# PADCFG_CTRL0_CFG0 register map
Vendor: Texas Instruments
Registers are 32-bit, access per field, reset 0x8214007 unless marked. A register's access mark holds for its fields unless they carry their own. Offsets are as the file gives them; [hi:lo] are bit positions; {n}, {i} and the like mark numbered series; 'fields as' and 'values as' point back to an identical list.

## PADCFG_CTRL0_CFG0 (part 2 of 2)
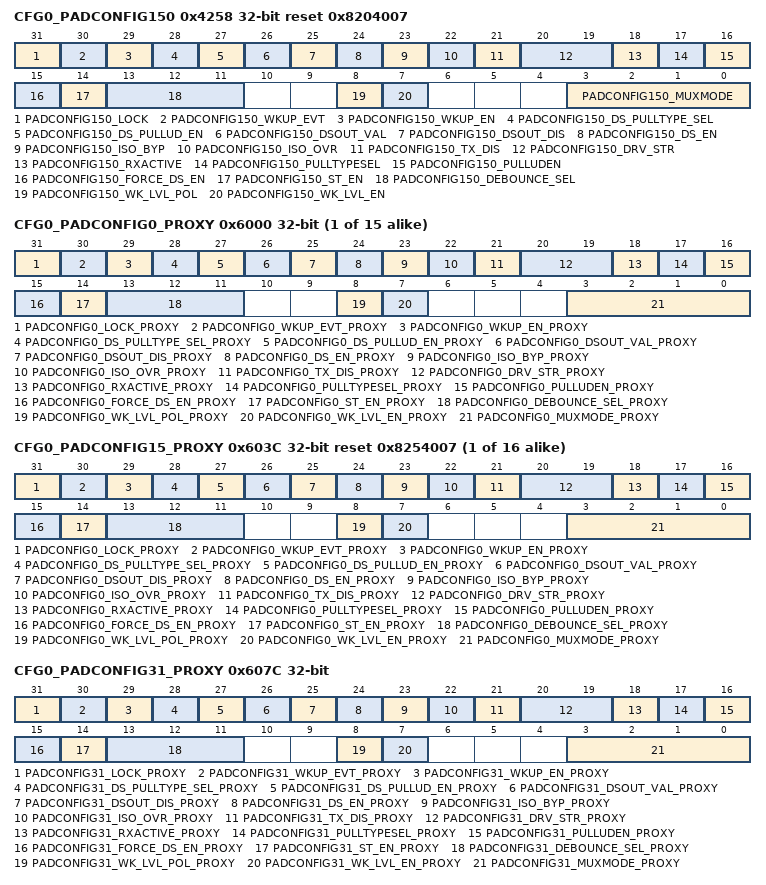
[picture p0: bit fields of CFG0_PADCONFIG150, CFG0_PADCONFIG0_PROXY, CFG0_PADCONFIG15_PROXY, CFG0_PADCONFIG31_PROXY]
0x4258 CFG0_PADCONFIG150 reset 0x8204007
  [31] PADCONFIG150_LOCK rw — Lock 0 - Padconfig register is unlocked 1 - Padconfig register is locked from further writes
  [30] PADCONFIG150_WKUP_EVT ro — Wakeup event status 0 - No wake event on pin 1 - Wake event occurred on pin
  [29] PADCONFIG150_WKUP_EN rw — Wakeup enable 0 - Wakeup operation disabled 1 - Wakeup operation enabled
  [28] PADCONFIG150_DS_PULLTYPE_SEL rw — Deep Sleep pull-up/down selection 0 - Offmode pulldown selected 1 - Offmode pullup selected
  [27] PADCONFIG150_DS_PULLUD_EN rw — Deep Sleep pull-up/down enable (active low) 0 - Pullup / pulldown is enabled 1 - Pullup / pulldown is disabled
  [26] PADCONFIG150_DSOUT_VAL rw — Deep Sleep output value 0 - Output value is 0 1 - Output value is 1
  [25] PADCONFIG150_DSOUT_DIS rw — Deep Sleep output disable 0 - Output enabled 1 - Output disabled
  [24] PADCONFIG150_DS_EN rw — Deep Sleep override control 0 - IO keeps its previous state when Deep Sleep mode is active 1 - IO state is forced to OFF mode value when Deep Sleep mode is active
  [23] PADCONFIG150_ISO_BYP rw — Isolation Bypass 0 - IO isolation is preserved 1 - IO isolation is bypassed
  [22] PADCONFIG150_ISO_OVR rw — Isolation Override 0 - IO isolation is preserved 1 - IO isolation is overridden
  [21] PADCONFIG150_TX_DIS rw — Driver Disable 0 - Driver is enabled 1 - Driver is disabled
  [20:19] PADCONFIG150_DRV_STR rw — Drive Strength Control . Selects the drive strength value for LVCMOS pins. (Does not apply to other pin types)
  [18] PADCONFIG150_RXACTIVE rw — Input enable for the Pad 0 - Receiver disabled 1 - Receiver enabled
  [17] PADCONFIG150_PULLTYPESEL rw — Pad Pullup / Pulldown type selection 0 - Pulldown selected 1 - Pullup selected
  [16] PADCONFIG150_PULLUDEN rw — Pad Pullup / Pulldown enable. This is an active low signal. 0 - Pullup / Pulldown enabled 1 - Pullup / Pulldown disabled
  [15] PADCONFIG150_FORCE_DS_EN rw — Enable pad Deep Sleep controls by overriding WKUP DM gating 0 - Deep Sleep pad controls are gated by the WKUP DM 1 - Activate Deep Sleep pad controls (override WKUP DM gating logic)
  [14] PADCONFIG150_ST_EN rw — Receiver Schmitt Trigger enable 0 - Schmitt trigger input disabled 1 - Schmitt trigger input enabled
  [13:11] PADCONFIG150_DEBOUNCE_SEL rw — Selects the debouce period for the pad.
  [8] PADCONFIG150_WK_LVL_POL rw — Level Sensitive Wakeup Polarity This bit is not relevant unless wk_lvl_en is set to 1'b1. 0 - Low. A low (0) value on the pin causes a wakeup 1 - High. A high (1) value on the pin causes a wakeup
  [7] PADCONFIG150_WK_LVL_EN rw — Level Sensitive Wakeup Enable 0 - Disabled. Wakeup is triggered by change of the pin input value 1 - Enabled. Wakeup is triggered when the pin matches the value specified by wk_lvl_pol. The chosen polarity must be maintained. (e.g. until wakeup completion is confirmed)
  [3:0] PADCONFIG150_MUXMODE rw — Pad functional signal mux selection Field values (others are reserved): 4'b0000 - Mux Mode 0 4'b0001 - Mux Mode 1 4'b0010 - Mux Mode 2 4'b0011 - Mux Mode 3 4'b0100 - Mux Mode 4 4'b0101 - Mux Mode 5 4'b0110 - Mux Mode 6 4'b0111 - Mux Mode 7 4'b1000 - Mux Mode 8 4'b1001 - Mux Mode 9 4'b1010 - Mux Mode 10 4'b1011 - Mux Mode 11 4'b1100 - Mux Mode 12 4'b1101 - Mux Mode 13 4'b1110 - Mux Mode 14 4'b1111 - Mux Mode 15
0x5008 CFG0_LOCK1_KICK0 rw reset 0x0
  [31:0] LOCK1_KICK0 — - KICK0 component
0x500C CFG0_LOCK1_KICK1 rw reset 0x0
  [31:0] LOCK1_KICK1 — - KICK1 component
{0x5100+4i} CFG0_CLAIMREG_P1_R{i}_READONLY ro reset 0x0 (i=0..4)
  [31:0] CLAIMREG_P1_R{i}_READONLY — Claim bits for Partition 1
{0x6000+4i} CFG0_PADCONFIG{i}_PROXY (i=0..14)
  [31] PADCONFIG{i}_LOCK_PROXY rw — Lock 0 - Padconfig register is unlocked 1 - Padconfig register is locked from further writes
  [30] PADCONFIG{i}_WKUP_EVT_PROXY ro — Wakeup event status 0 - No wake event on pin 1 - Wake event occurred on pin
  [29] PADCONFIG{i}_WKUP_EN_PROXY rw — Wakeup enable 0 - Wakeup operation disabled 1 - Wakeup operation enabled
  [28] PADCONFIG{i}_DS_PULLTYPE_SEL_PROXY rw — Deep Sleep pull-up/down selection 0 - Offmode pulldown selected 1 - Offmode pullup selected
  [27] PADCONFIG{i}_DS_PULLUD_EN_PROXY rw — Deep Sleep pull-up/down enable (active low) 0 - Pullup / pulldown is enabled 1 - Pullup / pulldown is disabled
  [26] PADCONFIG{i}_DSOUT_VAL_PROXY rw — Deep Sleep output value 0 - Output value is 0 1 - Output value is 1
  [25] PADCONFIG{i}_DSOUT_DIS_PROXY rw — Deep Sleep output disable 0 - Output enabled 1 - Output disabled
  [24] PADCONFIG{i}_DS_EN_PROXY rw — Deep Sleep override control 0 - IO keeps its previous state when Deep Sleep mode is active 1 - IO state is forced to OFF mode value when Deep Sleep mode is active
  [23] PADCONFIG{i}_ISO_BYP_PROXY rw — Isolation Bypass 0 - IO isolation is preserved 1 - IO isolation is bypassed
  [22] PADCONFIG{i}_ISO_OVR_PROXY rw — Isolation Override 0 - IO isolation is preserved 1 - IO isolation is overridden
  [21] PADCONFIG{i}_TX_DIS_PROXY rw — Driver Disable 0 - Driver is enabled 1 - Driver is disabled
  [20:19] PADCONFIG{i}_DRV_STR_PROXY rw — Drive Strength Control . Selects the drive strength value for LVCMOS pins. (Does not apply to other pin types)
  [18] PADCONFIG{i}_RXACTIVE_PROXY rw — Input enable for the Pad 0 - Receiver disabled 1 - Receiver enabled
  [17] PADCONFIG{i}_PULLTYPESEL_PROXY rw — Pad Pullup / Pulldown type selection 0 - Pulldown selected 1 - Pullup selected
  [16] PADCONFIG{i}_PULLUDEN_PROXY rw — Pad Pullup / Pulldown enable. This is an active low signal. 0 - Pullup / Pulldown enabled 1 - Pullup / Pulldown disabled
  [15] PADCONFIG{i}_FORCE_DS_EN_PROXY rw — Enable pad Deep Sleep controls by overriding WKUP DM gating 0 - Deep Sleep pad controls are gated by the WKUP DM 1 - Activate Deep Sleep pad controls (override WKUP DM gating logic)
  [14] PADCONFIG{i}_ST_EN_PROXY rw — Receiver Schmitt Trigger enable 0 - Schmitt trigger input disabled 1 - Schmitt trigger input enabled
  [13:11] PADCONFIG{i}_DEBOUNCE_SEL_PROXY rw — Selects the debouce period for the pad.
  [8] PADCONFIG{i}_WK_LVL_POL_PROXY rw — Level Sensitive Wakeup Polarity This bit is not relevant unless wk_lvl_en is set to 1'b1. 0 - Low. A low (0) value on the pin causes a wakeup 1 - High. A high (1) value on the pin causes a wakeup
  [7] PADCONFIG{i}_WK_LVL_EN_PROXY rw — Level Sensitive Wakeup Enable 0 - Disabled. Wakeup is triggered by change of the pin input value 1 - Enabled. Wakeup is triggered when the pin matches the value specified by wk_lvl_pol. The chosen polarity must be maintained. (e.g. until wakeup completion is confirmed)
  [3:0] PADCONFIG{i}_MUXMODE_PROXY rw — Pad functional signal mux selection Field values (others are reserved): 4'b0000 - Mux Mode 0 4'b0001 - Mux Mode 1 4'b0010 - Mux Mode 2 4'b0011 - Mux Mode 3 4'b0100 - Mux Mode 4 4'b0101 - Mux Mode 5 4'b0110 - Mux Mode 6 4'b0111 - Mux Mode 7 4'b1000 - Mux Mode 8 4'b1001 - Mux Mode 9 4'b1010 - Mux Mode 10 4'b1011 - Mux Mode 11 4'b1100 - Mux Mode 12 4'b1101 - Mux Mode 13 4'b1110 - Mux Mode 14 4'b1111 - Mux Mode 15
{0x6000+4i} CFG0_PADCONFIG{i}_PROXY reset 0x8254007 (i=15..30)
  fields as CFG0_PADCONFIG0_PROXY
0x607C CFG0_PADCONFIG31_PROXY
  [31] PADCONFIG31_LOCK_PROXY rw — Lock 0 - Padconfig register is unlocked 1 - Padconfig register is locked from further writes
  [30] PADCONFIG31_WKUP_EVT_PROXY ro — Wakeup event status 0 - No wake event on pin 1 - Wake event occurred on pin
  [29] PADCONFIG31_WKUP_EN_PROXY rw — Wakeup enable 0 - Wakeup operation disabled 1 - Wakeup operation enabled
  [28] PADCONFIG31_DS_PULLTYPE_SEL_PROXY rw — Deep Sleep pull-up/down selection 0 - Offmode pulldown selected 1 - Offmode pullup selected
  [27] PADCONFIG31_DS_PULLUD_EN_PROXY rw — Deep Sleep pull-up/down enable (active low) 0 - Pullup / pulldown is enabled 1 - Pullup / pulldown is disabled
  [26] PADCONFIG31_DSOUT_VAL_PROXY rw — Deep Sleep output value 0 - Output value is 0 1 - Output value is 1
  [25] PADCONFIG31_DSOUT_DIS_PROXY rw — Deep Sleep output disable 0 - Output enabled 1 - Output disabled
  [24] PADCONFIG31_DS_EN_PROXY rw — Deep Sleep override control 0 - IO keeps its previous state when Deep Sleep mode is active 1 - IO state is forced to OFF mode value when Deep Sleep mode is active
  [23] PADCONFIG31_ISO_BYP_PROXY rw — Isolation Bypass 0 - IO isolation is preserved 1 - IO isolation is bypassed
  [22] PADCONFIG31_ISO_OVR_PROXY rw — Isolation Override 0 - IO isolation is preserved 1 - IO isolation is overridden
  [21] PADCONFIG31_TX_DIS_PROXY rw — Driver Disable 0 - Driver is enabled 1 - Driver is disabled
  [20:19] PADCONFIG31_DRV_STR_PROXY rw — Drive Strength Control . Selects the drive strength value for LVCMOS pins. (Does not apply to other pin types)
  [18] PADCONFIG31_RXACTIVE_PROXY rw — Input enable for the Pad 0 - Receiver disabled 1 - Receiver enabled
  [17] PADCONFIG31_PULLTYPESEL_PROXY rw — Pad Pullup / Pulldown type selection 0 - Pulldown selected 1 - Pullup selected
  [16] PADCONFIG31_PULLUDEN_PROXY rw — Pad Pullup / Pulldown enable. This is an active low signal. 0 - Pullup / Pulldown enabled 1 - Pullup / Pulldown disabled
  [15] PADCONFIG31_FORCE_DS_EN_PROXY rw — Enable pad Deep Sleep controls by overriding WKUP DM gating 0 - Deep Sleep pad controls are gated by the WKUP DM 1 - Activate Deep Sleep pad controls (override WKUP DM gating logic)
  [14] PADCONFIG31_ST_EN_PROXY rw — Receiver Schmitt Trigger enable 0 - Schmitt trigger input disabled 1 - Schmitt trigger input enabled
  [13:11] PADCONFIG31_DEBOUNCE_SEL_PROXY rw — Selects the debouce period for the pad.
  [8] PADCONFIG31_WK_LVL_POL_PROXY rw — Level Sensitive Wakeup Polarity This bit is not relevant unless wk_lvl_en is set to 1'b1. 0 - Low. A low (0) value on the pin causes a wakeup 1 - High. A high (1) value on the pin causes a wakeup
  [7] PADCONFIG31_WK_LVL_EN_PROXY rw — Level Sensitive Wakeup Enable 0 - Disabled. Wakeup is triggered by change of the pin input value 1 - Enabled. Wakeup is triggered when the pin matches the value specified by wk_lvl_pol. The chosen polarity must be maintained. (e.g. until wakeup completion is confirmed)
  [3:0] PADCONFIG31_MUXMODE_PROXY rw — Pad functional signal mux selection Field values (others are reserved): 4'b0000 - Mux Mode 0 4'b0001 - Mux Mode 1 4'b0010 - Mux Mode 2 4'b0011 - Mux Mode 3 4'b0100 - Mux Mode 4 4'b0101 - Mux Mode 5 4'b0110 - Mux Mode 6 4'b0111 - Mux Mode 7 4'b1000 - Mux Mode 8 4'b1001 - Mux Mode 9 4'b1010 - Mux Mode 10 4'b1011 - Mux Mode 11 4'b1100 - Mux Mode 12 4'b1101 - Mux Mode 13 4'b1110 - Mux Mode 14 4'b1111 - Mux Mode 15
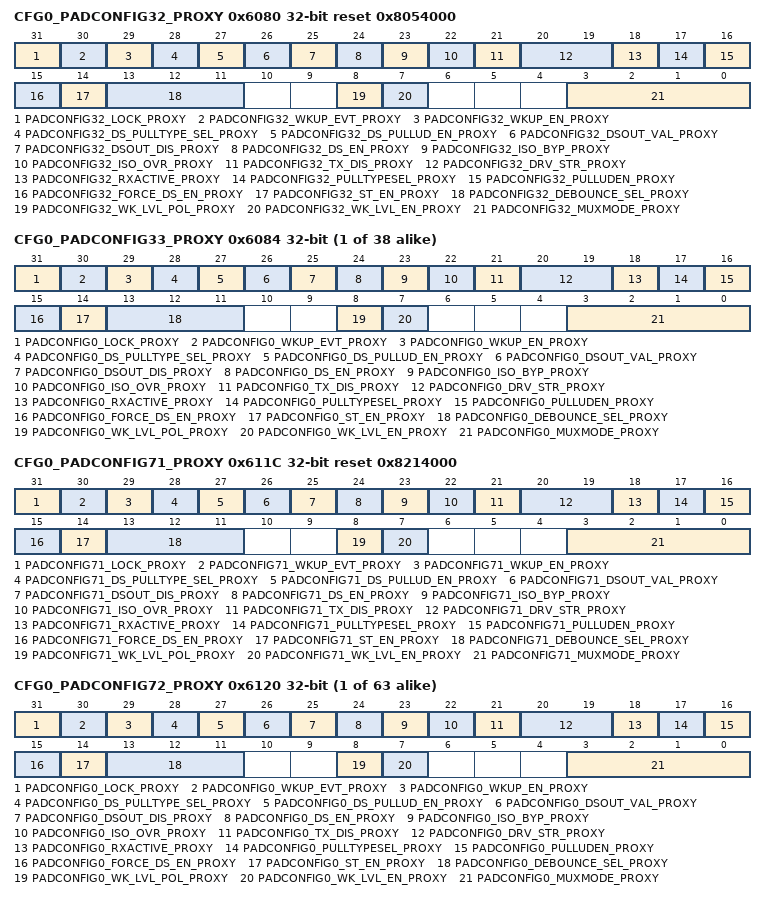
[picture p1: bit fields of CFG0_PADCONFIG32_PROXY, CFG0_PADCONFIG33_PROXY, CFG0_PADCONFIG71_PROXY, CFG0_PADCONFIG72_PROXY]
0x6080 CFG0_PADCONFIG32_PROXY reset 0x8054000
  [31] PADCONFIG32_LOCK_PROXY rw — Lock 0 - Padconfig register is unlocked 1 - Padconfig register is locked from further writes
  [30] PADCONFIG32_WKUP_EVT_PROXY ro — Wakeup event status 0 - No wake event on pin 1 - Wake event occurred on pin
  [29] PADCONFIG32_WKUP_EN_PROXY rw — Wakeup enable 0 - Wakeup operation disabled 1 - Wakeup operation enabled
  [28] PADCONFIG32_DS_PULLTYPE_SEL_PROXY rw — Deep Sleep pull-up/down selection 0 - Offmode pulldown selected 1 - Offmode pullup selected
  [27] PADCONFIG32_DS_PULLUD_EN_PROXY rw — Deep Sleep pull-up/down enable (active low) 0 - Pullup / pulldown is enabled 1 - Pullup / pulldown is disabled
  [26] PADCONFIG32_DSOUT_VAL_PROXY rw — Deep Sleep output value 0 - Output value is 0 1 - Output value is 1
  [25] PADCONFIG32_DSOUT_DIS_PROXY rw — Deep Sleep output disable 0 - Output enabled 1 - Output disabled
  [24] PADCONFIG32_DS_EN_PROXY rw — Deep Sleep override control 0 - IO keeps its previous state when Deep Sleep mode is active 1 - IO state is forced to OFF mode value when Deep Sleep mode is active
  [23] PADCONFIG32_ISO_BYP_PROXY rw — Isolation Bypass 0 - IO isolation is preserved 1 - IO isolation is bypassed
  [22] PADCONFIG32_ISO_OVR_PROXY rw — Isolation Override 0 - IO isolation is preserved 1 - IO isolation is overridden
  [21] PADCONFIG32_TX_DIS_PROXY rw — Driver Disable 0 - Driver is enabled 1 - Driver is disabled
  [20:19] PADCONFIG32_DRV_STR_PROXY rw — Drive Strength Control . Selects the drive strength value for LVCMOS pins. (Does not apply to other pin types)
  [18] PADCONFIG32_RXACTIVE_PROXY rw — Input enable for the Pad 0 - Receiver disabled 1 - Receiver enabled
  [17] PADCONFIG32_PULLTYPESEL_PROXY rw — Pad Pullup / Pulldown type selection 0 - Pulldown selected 1 - Pullup selected
  [16] PADCONFIG32_PULLUDEN_PROXY rw — Pad Pullup / Pulldown enable. This is an active low signal. 0 - Pullup / Pulldown enabled 1 - Pullup / Pulldown disabled
  [15] PADCONFIG32_FORCE_DS_EN_PROXY rw — Enable pad Deep Sleep controls by overriding WKUP DM gating 0 - Deep Sleep pad controls are gated by the WKUP DM 1 - Activate Deep Sleep pad controls (override WKUP DM gating logic)
  [14] PADCONFIG32_ST_EN_PROXY rw — Receiver Schmitt Trigger enable 0 - Schmitt trigger input disabled 1 - Schmitt trigger input enabled
  [13:11] PADCONFIG32_DEBOUNCE_SEL_PROXY rw — Selects the debouce period for the pad.
  [8] PADCONFIG32_WK_LVL_POL_PROXY rw — Level Sensitive Wakeup Polarity This bit is not relevant unless wk_lvl_en is set to 1'b1. 0 - Low. A low (0) value on the pin causes a wakeup 1 - High. A high (1) value on the pin causes a wakeup
  [7] PADCONFIG32_WK_LVL_EN_PROXY rw — Level Sensitive Wakeup Enable 0 - Disabled. Wakeup is triggered by change of the pin input value 1 - Enabled. Wakeup is triggered when the pin matches the value specified by wk_lvl_pol. The chosen polarity must be maintained. (e.g. until wakeup completion is confirmed)
  [3:0] PADCONFIG32_MUXMODE_PROXY rw — Pad functional signal mux selection Field values (others are reserved): 4'b0000 - Mux Mode 0 4'b0001 - Mux Mode 1 4'b0010 - Mux Mode 2 4'b0011 - Mux Mode 3 4'b0100 - Mux Mode 4 4'b0101 - Mux Mode 5 4'b0110 - Mux Mode 6 4'b0111 - Mux Mode 7 4'b1000 - Mux Mode 8 4'b1001 - Mux Mode 9 4'b1010 - Mux Mode 10 4'b1011 - Mux Mode 11 4'b1100 - Mux Mode 12 4'b1101 - Mux Mode 13 4'b1110 - Mux Mode 14 4'b1111 - Mux Mode 15
{0x6000+4i} CFG0_PADCONFIG{i}_PROXY (i=33..70)
  fields as CFG0_PADCONFIG0_PROXY
0x611C CFG0_PADCONFIG71_PROXY reset 0x8214000
  [31] PADCONFIG71_LOCK_PROXY rw — Lock 0 - Padconfig register is unlocked 1 - Padconfig register is locked from further writes
  [30] PADCONFIG71_WKUP_EVT_PROXY ro — Wakeup event status 0 - No wake event on pin 1 - Wake event occurred on pin
  [29] PADCONFIG71_WKUP_EN_PROXY rw — Wakeup enable 0 - Wakeup operation disabled 1 - Wakeup operation enabled
  [28] PADCONFIG71_DS_PULLTYPE_SEL_PROXY rw — Deep Sleep pull-up/down selection 0 - Offmode pulldown selected 1 - Offmode pullup selected
  [27] PADCONFIG71_DS_PULLUD_EN_PROXY rw — Deep Sleep pull-up/down enable (active low) 0 - Pullup / pulldown is enabled 1 - Pullup / pulldown is disabled
  [26] PADCONFIG71_DSOUT_VAL_PROXY rw — Deep Sleep output value 0 - Output value is 0 1 - Output value is 1
  [25] PADCONFIG71_DSOUT_DIS_PROXY rw — Deep Sleep output disable 0 - Output enabled 1 - Output disabled
  [24] PADCONFIG71_DS_EN_PROXY rw — Deep Sleep override control 0 - IO keeps its previous state when Deep Sleep mode is active 1 - IO state is forced to OFF mode value when Deep Sleep mode is active
  [23] PADCONFIG71_ISO_BYP_PROXY rw — Isolation Bypass 0 - IO isolation is preserved 1 - IO isolation is bypassed
  [22] PADCONFIG71_ISO_OVR_PROXY rw — Isolation Override 0 - IO isolation is preserved 1 - IO isolation is overridden
  [21] PADCONFIG71_TX_DIS_PROXY rw — Driver Disable 0 - Driver is enabled 1 - Driver is disabled
  [20:19] PADCONFIG71_DRV_STR_PROXY rw — Drive Strength Control . Selects the drive strength value for LVCMOS pins. (Does not apply to other pin types)
  [18] PADCONFIG71_RXACTIVE_PROXY rw — Input enable for the Pad 0 - Receiver disabled 1 - Receiver enabled
  [17] PADCONFIG71_PULLTYPESEL_PROXY rw — Pad Pullup / Pulldown type selection 0 - Pulldown selected 1 - Pullup selected
  [16] PADCONFIG71_PULLUDEN_PROXY rw — Pad Pullup / Pulldown enable. This is an active low signal. 0 - Pullup / Pulldown enabled 1 - Pullup / Pulldown disabled
  [15] PADCONFIG71_FORCE_DS_EN_PROXY rw — Enable pad Deep Sleep controls by overriding WKUP DM gating 0 - Deep Sleep pad controls are gated by the WKUP DM 1 - Activate Deep Sleep pad controls (override WKUP DM gating logic)
  [14] PADCONFIG71_ST_EN_PROXY rw — Receiver Schmitt Trigger enable 0 - Schmitt trigger input disabled 1 - Schmitt trigger input enabled
  [13:11] PADCONFIG71_DEBOUNCE_SEL_PROXY rw — Selects the debouce period for the pad.
  [8] PADCONFIG71_WK_LVL_POL_PROXY rw — Level Sensitive Wakeup Polarity This bit is not relevant unless wk_lvl_en is set to 1'b1. 0 - Low. A low (0) value on the pin causes a wakeup 1 - High. A high (1) value on the pin causes a wakeup
  [7] PADCONFIG71_WK_LVL_EN_PROXY rw — Level Sensitive Wakeup Enable 0 - Disabled. Wakeup is triggered by change of the pin input value 1 - Enabled. Wakeup is triggered when the pin matches the value specified by wk_lvl_pol. The chosen polarity must be maintained. (e.g. until wakeup completion is confirmed)
  [3:0] PADCONFIG71_MUXMODE_PROXY rw — Pad functional signal mux selection Field values (others are reserved): 4'b0000 - Mux Mode 0 4'b0001 - Mux Mode 1 4'b0010 - Mux Mode 2 4'b0011 - Mux Mode 3 4'b0100 - Mux Mode 4 4'b0101 - Mux Mode 5 4'b0110 - Mux Mode 6 4'b0111 - Mux Mode 7 4'b1000 - Mux Mode 8 4'b1001 - Mux Mode 9 4'b1010 - Mux Mode 10 4'b1011 - Mux Mode 11 4'b1100 - Mux Mode 12 4'b1101 - Mux Mode 13 4'b1110 - Mux Mode 14 4'b1111 - Mux Mode 15
{0x6000+4i} CFG0_PADCONFIG{i}_PROXY (i=72..134)
  fields as CFG0_PADCONFIG0_PROXY
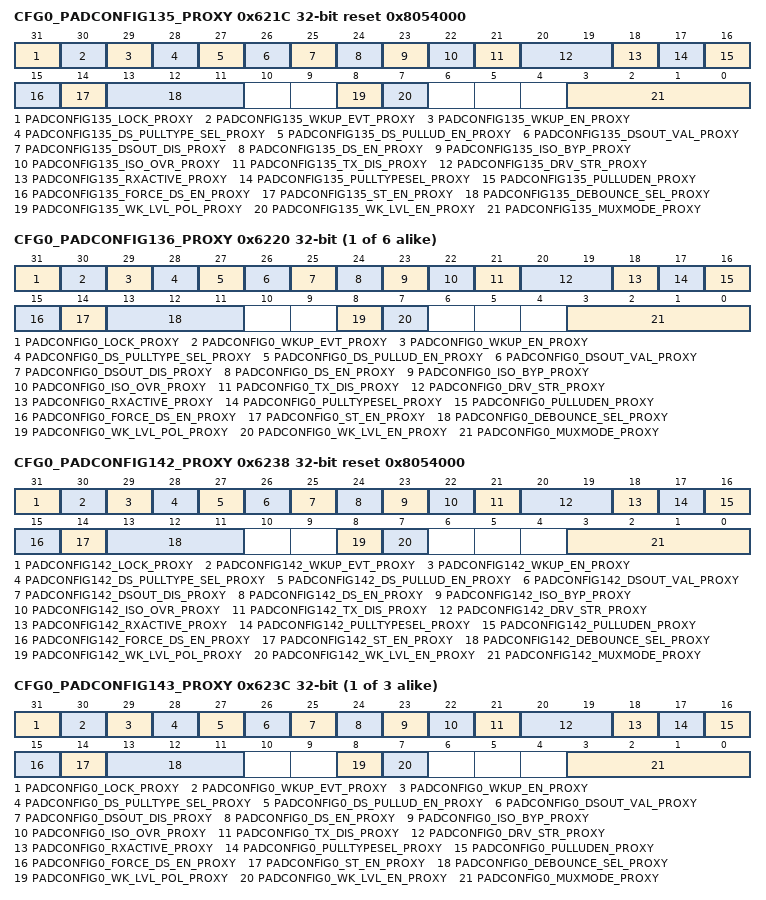
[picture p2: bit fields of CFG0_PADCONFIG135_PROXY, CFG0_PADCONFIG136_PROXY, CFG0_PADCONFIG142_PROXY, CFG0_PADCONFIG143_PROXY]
0x621C CFG0_PADCONFIG135_PROXY reset 0x8054000
  [31] PADCONFIG135_LOCK_PROXY rw — Lock 0 - Padconfig register is unlocked 1 - Padconfig register is locked from further writes
  [30] PADCONFIG135_WKUP_EVT_PROXY ro — Wakeup event status 0 - No wake event on pin 1 - Wake event occurred on pin
  [29] PADCONFIG135_WKUP_EN_PROXY rw — Wakeup enable 0 - Wakeup operation disabled 1 - Wakeup operation enabled
  [28] PADCONFIG135_DS_PULLTYPE_SEL_PROXY rw — Deep Sleep pull-up/down selection 0 - Offmode pulldown selected 1 - Offmode pullup selected
  [27] PADCONFIG135_DS_PULLUD_EN_PROXY rw — Deep Sleep pull-up/down enable (active low) 0 - Pullup / pulldown is enabled 1 - Pullup / pulldown is disabled
  [26] PADCONFIG135_DSOUT_VAL_PROXY rw — Deep Sleep output value 0 - Output value is 0 1 - Output value is 1
  [25] PADCONFIG135_DSOUT_DIS_PROXY rw — Deep Sleep output disable 0 - Output enabled 1 - Output disabled
  [24] PADCONFIG135_DS_EN_PROXY rw — Deep Sleep override control 0 - IO keeps its previous state when Deep Sleep mode is active 1 - IO state is forced to OFF mode value when Deep Sleep mode is active
  [23] PADCONFIG135_ISO_BYP_PROXY rw — Isolation Bypass 0 - IO isolation is preserved 1 - IO isolation is bypassed
  [22] PADCONFIG135_ISO_OVR_PROXY rw — Isolation Override 0 - IO isolation is preserved 1 - IO isolation is overridden
  [21] PADCONFIG135_TX_DIS_PROXY rw — Driver Disable 0 - Driver is enabled 1 - Driver is disabled
  [20:19] PADCONFIG135_DRV_STR_PROXY rw — Drive Strength Control . Selects the drive strength value for LVCMOS pins. (Does not apply to other pin types)
  [18] PADCONFIG135_RXACTIVE_PROXY rw — Input enable for the Pad 0 - Receiver disabled 1 - Receiver enabled
  [17] PADCONFIG135_PULLTYPESEL_PROXY rw — Pad Pullup / Pulldown type selection 0 - Pulldown selected 1 - Pullup selected
  [16] PADCONFIG135_PULLUDEN_PROXY rw — Pad Pullup / Pulldown enable. This is an active low signal. 0 - Pullup / Pulldown enabled 1 - Pullup / Pulldown disabled
  [15] PADCONFIG135_FORCE_DS_EN_PROXY rw — Enable pad Deep Sleep controls by overriding WKUP DM gating 0 - Deep Sleep pad controls are gated by the WKUP DM 1 - Activate Deep Sleep pad controls (override WKUP DM gating logic)
  [14] PADCONFIG135_ST_EN_PROXY rw — Receiver Schmitt Trigger enable 0 - Schmitt trigger input disabled 1 - Schmitt trigger input enabled
  [13:11] PADCONFIG135_DEBOUNCE_SEL_PROXY rw — Selects the debouce period for the pad.
  [8] PADCONFIG135_WK_LVL_POL_PROXY rw — Level Sensitive Wakeup Polarity This bit is not relevant unless wk_lvl_en is set to 1'b1. 0 - Low. A low (0) value on the pin causes a wakeup 1 - High. A high (1) value on the pin causes a wakeup
  [7] PADCONFIG135_WK_LVL_EN_PROXY rw — Level Sensitive Wakeup Enable 0 - Disabled. Wakeup is triggered by change of the pin input value 1 - Enabled. Wakeup is triggered when the pin matches the value specified by wk_lvl_pol. The chosen polarity must be maintained. (e.g. until wakeup completion is confirmed)
  [3:0] PADCONFIG135_MUXMODE_PROXY rw — Pad functional signal mux selection Field values (others are reserved): 4'b0000 - Mux Mode 0 4'b0001 - Mux Mode 1 4'b0010 - Mux Mode 2 4'b0011 - Mux Mode 3 4'b0100 - Mux Mode 4 4'b0101 - Mux Mode 5 4'b0110 - Mux Mode 6 4'b0111 - Mux Mode 7 4'b1000 - Mux Mode 8 4'b1001 - Mux Mode 9 4'b1010 - Mux Mode 10 4'b1011 - Mux Mode 11 4'b1100 - Mux Mode 12 4'b1101 - Mux Mode 13 4'b1110 - Mux Mode 14 4'b1111 - Mux Mode 15
{0x6000+4i} CFG0_PADCONFIG{i}_PROXY (i=136..141)
  fields as CFG0_PADCONFIG0_PROXY
0x6238 CFG0_PADCONFIG142_PROXY reset 0x8054000
  [31] PADCONFIG142_LOCK_PROXY rw — Lock 0 - Padconfig register is unlocked 1 - Padconfig register is locked from further writes
  [30] PADCONFIG142_WKUP_EVT_PROXY ro — Wakeup event status 0 - No wake event on pin 1 - Wake event occurred on pin
  [29] PADCONFIG142_WKUP_EN_PROXY rw — Wakeup enable 0 - Wakeup operation disabled 1 - Wakeup operation enabled
  [28] PADCONFIG142_DS_PULLTYPE_SEL_PROXY rw — Deep Sleep pull-up/down selection 0 - Offmode pulldown selected 1 - Offmode pullup selected
  [27] PADCONFIG142_DS_PULLUD_EN_PROXY rw — Deep Sleep pull-up/down enable (active low) 0 - Pullup / pulldown is enabled 1 - Pullup / pulldown is disabled
  [26] PADCONFIG142_DSOUT_VAL_PROXY rw — Deep Sleep output value 0 - Output value is 0 1 - Output value is 1
  [25] PADCONFIG142_DSOUT_DIS_PROXY rw — Deep Sleep output disable 0 - Output enabled 1 - Output disabled
  [24] PADCONFIG142_DS_EN_PROXY rw — Deep Sleep override control 0 - IO keeps its previous state when Deep Sleep mode is active 1 - IO state is forced to OFF mode value when Deep Sleep mode is active
  [23] PADCONFIG142_ISO_BYP_PROXY rw — Isolation Bypass 0 - IO isolation is preserved 1 - IO isolation is bypassed
  [22] PADCONFIG142_ISO_OVR_PROXY rw — Isolation Override 0 - IO isolation is preserved 1 - IO isolation is overridden
  [21] PADCONFIG142_TX_DIS_PROXY rw — Driver Disable 0 - Driver is enabled 1 - Driver is disabled
  [20:19] PADCONFIG142_DRV_STR_PROXY rw — Drive Strength Control . Selects the drive strength value for LVCMOS pins. (Does not apply to other pin types)
  [18] PADCONFIG142_RXACTIVE_PROXY rw — Input enable for the Pad 0 - Receiver disabled 1 - Receiver enabled
  [17] PADCONFIG142_PULLTYPESEL_PROXY rw — Pad Pullup / Pulldown type selection 0 - Pulldown selected 1 - Pullup selected
  [16] PADCONFIG142_PULLUDEN_PROXY rw — Pad Pullup / Pulldown enable. This is an active low signal. 0 - Pullup / Pulldown enabled 1 - Pullup / Pulldown disabled
  [15] PADCONFIG142_FORCE_DS_EN_PROXY rw — Enable pad Deep Sleep controls by overriding WKUP DM gating 0 - Deep Sleep pad controls are gated by the WKUP DM 1 - Activate Deep Sleep pad controls (override WKUP DM gating logic)
  [14] PADCONFIG142_ST_EN_PROXY rw — Receiver Schmitt Trigger enable 0 - Schmitt trigger input disabled 1 - Schmitt trigger input enabled
  [13:11] PADCONFIG142_DEBOUNCE_SEL_PROXY rw — Selects the debouce period for the pad.
  [8] PADCONFIG142_WK_LVL_POL_PROXY rw — Level Sensitive Wakeup Polarity This bit is not relevant unless wk_lvl_en is set to 1'b1. 0 - Low. A low (0) value on the pin causes a wakeup 1 - High. A high (1) value on the pin causes a wakeup
  [7] PADCONFIG142_WK_LVL_EN_PROXY rw — Level Sensitive Wakeup Enable 0 - Disabled. Wakeup is triggered by change of the pin input value 1 - Enabled. Wakeup is triggered when the pin matches the value specified by wk_lvl_pol. The chosen polarity must be maintained. (e.g. until wakeup completion is confirmed)
  [3:0] PADCONFIG142_MUXMODE_PROXY rw — Pad functional signal mux selection Field values (others are reserved): 4'b0000 - Mux Mode 0 4'b0001 - Mux Mode 1 4'b0010 - Mux Mode 2 4'b0011 - Mux Mode 3 4'b0100 - Mux Mode 4 4'b0101 - Mux Mode 5 4'b0110 - Mux Mode 6 4'b0111 - Mux Mode 7 4'b1000 - Mux Mode 8 4'b1001 - Mux Mode 9 4'b1010 - Mux Mode 10 4'b1011 - Mux Mode 11 4'b1100 - Mux Mode 12 4'b1101 - Mux Mode 13 4'b1110 - Mux Mode 14 4'b1111 - Mux Mode 15
{0x6000+4i} CFG0_PADCONFIG{i}_PROXY (i=143..145)
  fields as CFG0_PADCONFIG0_PROXY
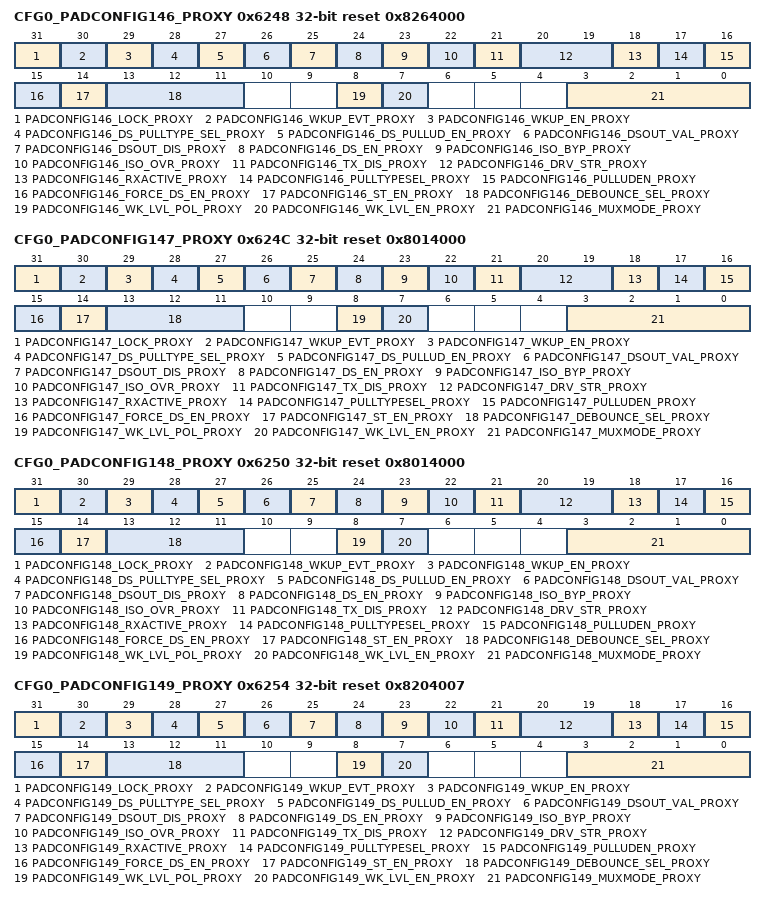
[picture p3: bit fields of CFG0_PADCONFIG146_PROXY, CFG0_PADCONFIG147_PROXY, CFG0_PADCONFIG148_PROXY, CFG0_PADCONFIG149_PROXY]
0x6248 CFG0_PADCONFIG146_PROXY reset 0x8264000
  [31] PADCONFIG146_LOCK_PROXY rw — Lock 0 - Padconfig register is unlocked 1 - Padconfig register is locked from further writes
  [30] PADCONFIG146_WKUP_EVT_PROXY ro — Wakeup event status 0 - No wake event on pin 1 - Wake event occurred on pin
  [29] PADCONFIG146_WKUP_EN_PROXY rw — Wakeup enable 0 - Wakeup operation disabled 1 - Wakeup operation enabled
  [28] PADCONFIG146_DS_PULLTYPE_SEL_PROXY rw — Deep Sleep pull-up/down selection 0 - Offmode pulldown selected 1 - Offmode pullup selected
  [27] PADCONFIG146_DS_PULLUD_EN_PROXY rw — Deep Sleep pull-up/down enable (active low) 0 - Pullup / pulldown is enabled 1 - Pullup / pulldown is disabled
  [26] PADCONFIG146_DSOUT_VAL_PROXY rw — Deep Sleep output value 0 - Output value is 0 1 - Output value is 1
  [25] PADCONFIG146_DSOUT_DIS_PROXY rw — Deep Sleep output disable 0 - Output enabled 1 - Output disabled
  [24] PADCONFIG146_DS_EN_PROXY rw — Deep Sleep override control 0 - IO keeps its previous state when Deep Sleep mode is active 1 - IO state is forced to OFF mode value when Deep Sleep mode is active
  [23] PADCONFIG146_ISO_BYP_PROXY rw — Isolation Bypass 0 - IO isolation is preserved 1 - IO isolation is bypassed
  [22] PADCONFIG146_ISO_OVR_PROXY rw — Isolation Override 0 - IO isolation is preserved 1 - IO isolation is overridden
  [21] PADCONFIG146_TX_DIS_PROXY rw — Driver Disable 0 - Driver is enabled 1 - Driver is disabled
  [20:19] PADCONFIG146_DRV_STR_PROXY rw — Drive Strength Control . Selects the drive strength value for LVCMOS pins. (Does not apply to other pin types)
  [18] PADCONFIG146_RXACTIVE_PROXY rw — Input enable for the Pad 0 - Receiver disabled 1 - Receiver enabled
  [17] PADCONFIG146_PULLTYPESEL_PROXY rw — Pad Pullup / Pulldown type selection 0 - Pulldown selected 1 - Pullup selected
  [16] PADCONFIG146_PULLUDEN_PROXY rw — Pad Pullup / Pulldown enable. This is an active low signal. 0 - Pullup / Pulldown enabled 1 - Pullup / Pulldown disabled
  [15] PADCONFIG146_FORCE_DS_EN_PROXY rw — Enable pad Deep Sleep controls by overriding WKUP DM gating 0 - Deep Sleep pad controls are gated by the WKUP DM 1 - Activate Deep Sleep pad controls (override WKUP DM gating logic)
  [14] PADCONFIG146_ST_EN_PROXY rw — Receiver Schmitt Trigger enable 0 - Schmitt trigger input disabled 1 - Schmitt trigger input enabled
  [13:11] PADCONFIG146_DEBOUNCE_SEL_PROXY rw — Selects the debouce period for the pad.
  [8] PADCONFIG146_WK_LVL_POL_PROXY rw — Level Sensitive Wakeup Polarity This bit is not relevant unless wk_lvl_en is set to 1'b1. 0 - Low. A low (0) value on the pin causes a wakeup 1 - High. A high (1) value on the pin causes a wakeup
  [7] PADCONFIG146_WK_LVL_EN_PROXY rw — Level Sensitive Wakeup Enable 0 - Disabled. Wakeup is triggered by change of the pin input value 1 - Enabled. Wakeup is triggered when the pin matches the value specified by wk_lvl_pol. The chosen polarity must be maintained. (e.g. until wakeup completion is confirmed)
  [3:0] PADCONFIG146_MUXMODE_PROXY rw — Pad functional signal mux selection Field values (others are reserved): 4'b0000 - Mux Mode 0 4'b0001 - Mux Mode 1 4'b0010 - Mux Mode 2 4'b0011 - Mux Mode 3 4'b0100 - Mux Mode 4 4'b0101 - Mux Mode 5 4'b0110 - Mux Mode 6 4'b0111 - Mux Mode 7 4'b1000 - Mux Mode 8 4'b1001 - Mux Mode 9 4'b1010 - Mux Mode 10 4'b1011 - Mux Mode 11 4'b1100 - Mux Mode 12 4'b1101 - Mux Mode 13 4'b1110 - Mux Mode 14 4'b1111 - Mux Mode 15
0x624C CFG0_PADCONFIG147_PROXY reset 0x8014000
  [31] PADCONFIG147_LOCK_PROXY rw — Lock 0 - Padconfig register is unlocked 1 - Padconfig register is locked from further writes
  [30] PADCONFIG147_WKUP_EVT_PROXY ro — Wakeup event status 0 - No wake event on pin 1 - Wake event occurred on pin
  [29] PADCONFIG147_WKUP_EN_PROXY rw — Wakeup enable 0 - Wakeup operation disabled 1 - Wakeup operation enabled
  [28] PADCONFIG147_DS_PULLTYPE_SEL_PROXY rw — Deep Sleep pull-up/down selection 0 - Offmode pulldown selected 1 - Offmode pullup selected
  [27] PADCONFIG147_DS_PULLUD_EN_PROXY rw — Deep Sleep pull-up/down enable (active low) 0 - Pullup / pulldown is enabled 1 - Pullup / pulldown is disabled
  [26] PADCONFIG147_DSOUT_VAL_PROXY rw — Deep Sleep output value 0 - Output value is 0 1 - Output value is 1
  [25] PADCONFIG147_DSOUT_DIS_PROXY rw — Deep Sleep output disable 0 - Output enabled 1 - Output disabled
  [24] PADCONFIG147_DS_EN_PROXY rw — Deep Sleep override control 0 - IO keeps its previous state when Deep Sleep mode is active 1 - IO state is forced to OFF mode value when Deep Sleep mode is active
  [23] PADCONFIG147_ISO_BYP_PROXY rw — Isolation Bypass 0 - IO isolation is preserved 1 - IO isolation is bypassed
  [22] PADCONFIG147_ISO_OVR_PROXY rw — Isolation Override 0 - IO isolation is preserved 1 - IO isolation is overridden
  [21] PADCONFIG147_TX_DIS_PROXY rw — Driver Disable 0 - Driver is enabled 1 - Driver is disabled
  [20:19] PADCONFIG147_DRV_STR_PROXY rw — Drive Strength Control . Selects the drive strength value for LVCMOS pins. (Does not apply to other pin types)
  [18] PADCONFIG147_RXACTIVE_PROXY rw — Input enable for the Pad 0 - Receiver disabled 1 - Receiver enabled
  [17] PADCONFIG147_PULLTYPESEL_PROXY rw — Pad Pullup / Pulldown type selection 0 - Pulldown selected 1 - Pullup selected
  [16] PADCONFIG147_PULLUDEN_PROXY rw — Pad Pullup / Pulldown enable. This is an active low signal. 0 - Pullup / Pulldown enabled 1 - Pullup / Pulldown disabled
  [15] PADCONFIG147_FORCE_DS_EN_PROXY rw — Enable pad Deep Sleep controls by overriding WKUP DM gating 0 - Deep Sleep pad controls are gated by the WKUP DM 1 - Activate Deep Sleep pad controls (override WKUP DM gating logic)
  [14] PADCONFIG147_ST_EN_PROXY rw — Receiver Schmitt Trigger enable 0 - Schmitt trigger input disabled 1 - Schmitt trigger input enabled
  [13:11] PADCONFIG147_DEBOUNCE_SEL_PROXY rw — Selects the debouce period for the pad.
  [8] PADCONFIG147_WK_LVL_POL_PROXY rw — Level Sensitive Wakeup Polarity This bit is not relevant unless wk_lvl_en is set to 1'b1. 0 - Low. A low (0) value on the pin causes a wakeup 1 - High. A high (1) value on the pin causes a wakeup
  [7] PADCONFIG147_WK_LVL_EN_PROXY rw — Level Sensitive Wakeup Enable 0 - Disabled. Wakeup is triggered by change of the pin input value 1 - Enabled. Wakeup is triggered when the pin matches the value specified by wk_lvl_pol. The chosen polarity must be maintained. (e.g. until wakeup completion is confirmed)
  [3:0] PADCONFIG147_MUXMODE_PROXY rw — Pad functional signal mux selection Field values (others are reserved): 4'b0000 - Mux Mode 0 4'b0001 - Mux Mode 1 4'b0010 - Mux Mode 2 4'b0011 - Mux Mode 3 4'b0100 - Mux Mode 4 4'b0101 - Mux Mode 5 4'b0110 - Mux Mode 6 4'b0111 - Mux Mode 7 4'b1000 - Mux Mode 8 4'b1001 - Mux Mode 9 4'b1010 - Mux Mode 10 4'b1011 - Mux Mode 11 4'b1100 - Mux Mode 12 4'b1101 - Mux Mode 13 4'b1110 - Mux Mode 14 4'b1111 - Mux Mode 15
0x6250 CFG0_PADCONFIG148_PROXY reset 0x8014000
  [31] PADCONFIG148_LOCK_PROXY rw — Lock 0 - Padconfig register is unlocked 1 - Padconfig register is locked from further writes
  [30] PADCONFIG148_WKUP_EVT_PROXY ro — Wakeup event status 0 - No wake event on pin 1 - Wake event occurred on pin
  [29] PADCONFIG148_WKUP_EN_PROXY rw — Wakeup enable 0 - Wakeup operation disabled 1 - Wakeup operation enabled
  [28] PADCONFIG148_DS_PULLTYPE_SEL_PROXY rw — Deep Sleep pull-up/down selection 0 - Offmode pulldown selected 1 - Offmode pullup selected
  [27] PADCONFIG148_DS_PULLUD_EN_PROXY rw — Deep Sleep pull-up/down enable (active low) 0 - Pullup / pulldown is enabled 1 - Pullup / pulldown is disabled
  [26] PADCONFIG148_DSOUT_VAL_PROXY rw — Deep Sleep output value 0 - Output value is 0 1 - Output value is 1
  [25] PADCONFIG148_DSOUT_DIS_PROXY rw — Deep Sleep output disable 0 - Output enabled 1 - Output disabled
  [24] PADCONFIG148_DS_EN_PROXY rw — Deep Sleep override control 0 - IO keeps its previous state when Deep Sleep mode is active 1 - IO state is forced to OFF mode value when Deep Sleep mode is active
  [23] PADCONFIG148_ISO_BYP_PROXY rw — Isolation Bypass 0 - IO isolation is preserved 1 - IO isolation is bypassed
  [22] PADCONFIG148_ISO_OVR_PROXY rw — Isolation Override 0 - IO isolation is preserved 1 - IO isolation is overridden
  [21] PADCONFIG148_TX_DIS_PROXY rw — Driver Disable 0 - Driver is enabled 1 - Driver is disabled
  [20:19] PADCONFIG148_DRV_STR_PROXY rw — Drive Strength Control . Selects the drive strength value for LVCMOS pins. (Does not apply to other pin types)
  [18] PADCONFIG148_RXACTIVE_PROXY rw — Input enable for the Pad 0 - Receiver disabled 1 - Receiver enabled
  [17] PADCONFIG148_PULLTYPESEL_PROXY rw — Pad Pullup / Pulldown type selection 0 - Pulldown selected 1 - Pullup selected
  [16] PADCONFIG148_PULLUDEN_PROXY rw — Pad Pullup / Pulldown enable. This is an active low signal. 0 - Pullup / Pulldown enabled 1 - Pullup / Pulldown disabled
  [15] PADCONFIG148_FORCE_DS_EN_PROXY rw — Enable pad Deep Sleep controls by overriding WKUP DM gating 0 - Deep Sleep pad controls are gated by the WKUP DM 1 - Activate Deep Sleep pad controls (override WKUP DM gating logic)
  [14] PADCONFIG148_ST_EN_PROXY rw — Receiver Schmitt Trigger enable 0 - Schmitt trigger input disabled 1 - Schmitt trigger input enabled
  [13:11] PADCONFIG148_DEBOUNCE_SEL_PROXY rw — Selects the debouce period for the pad.
  [8] PADCONFIG148_WK_LVL_POL_PROXY rw — Level Sensitive Wakeup Polarity This bit is not relevant unless wk_lvl_en is set to 1'b1. 0 - Low. A low (0) value on the pin causes a wakeup 1 - High. A high (1) value on the pin causes a wakeup
  [7] PADCONFIG148_WK_LVL_EN_PROXY rw — Level Sensitive Wakeup Enable 0 - Disabled. Wakeup is triggered by change of the pin input value 1 - Enabled. Wakeup is triggered when the pin matches the value specified by wk_lvl_pol. The chosen polarity must be maintained. (e.g. until wakeup completion is confirmed)
  [3:0] PADCONFIG148_MUXMODE_PROXY rw — Pad functional signal mux selection Field values (others are reserved): 4'b0000 - Mux Mode 0 4'b0001 - Mux Mode 1 4'b0010 - Mux Mode 2 4'b0011 - Mux Mode 3 4'b0100 - Mux Mode 4 4'b0101 - Mux Mode 5 4'b0110 - Mux Mode 6 4'b0111 - Mux Mode 7 4'b1000 - Mux Mode 8 4'b1001 - Mux Mode 9 4'b1010 - Mux Mode 10 4'b1011 - Mux Mode 11 4'b1100 - Mux Mode 12 4'b1101 - Mux Mode 13 4'b1110 - Mux Mode 14 4'b1111 - Mux Mode 15
0x6254 CFG0_PADCONFIG149_PROXY reset 0x8204007
  [31] PADCONFIG149_LOCK_PROXY rw — Lock 0 - Padconfig register is unlocked 1 - Padconfig register is locked from further writes
  [30] PADCONFIG149_WKUP_EVT_PROXY ro — Wakeup event status 0 - No wake event on pin 1 - Wake event occurred on pin
  [29] PADCONFIG149_WKUP_EN_PROXY rw — Wakeup enable 0 - Wakeup operation disabled 1 - Wakeup operation enabled
  [28] PADCONFIG149_DS_PULLTYPE_SEL_PROXY rw — Deep Sleep pull-up/down selection 0 - Offmode pulldown selected 1 - Offmode pullup selected
  [27] PADCONFIG149_DS_PULLUD_EN_PROXY rw — Deep Sleep pull-up/down enable (active low) 0 - Pullup / pulldown is enabled 1 - Pullup / pulldown is disabled
  [26] PADCONFIG149_DSOUT_VAL_PROXY rw — Deep Sleep output value 0 - Output value is 0 1 - Output value is 1
  [25] PADCONFIG149_DSOUT_DIS_PROXY rw — Deep Sleep output disable 0 - Output enabled 1 - Output disabled
  [24] PADCONFIG149_DS_EN_PROXY rw — Deep Sleep override control 0 - IO keeps its previous state when Deep Sleep mode is active 1 - IO state is forced to OFF mode value when Deep Sleep mode is active
  [23] PADCONFIG149_ISO_BYP_PROXY rw — Isolation Bypass 0 - IO isolation is preserved 1 - IO isolation is bypassed
  [22] PADCONFIG149_ISO_OVR_PROXY rw — Isolation Override 0 - IO isolation is preserved 1 - IO isolation is overridden
  [21] PADCONFIG149_TX_DIS_PROXY rw — Driver Disable 0 - Driver is enabled 1 - Driver is disabled
  [20:19] PADCONFIG149_DRV_STR_PROXY rw — Drive Strength Control . Selects the drive strength value for LVCMOS pins. (Does not apply to other pin types)
  [18] PADCONFIG149_RXACTIVE_PROXY rw — Input enable for the Pad 0 - Receiver disabled 1 - Receiver enabled
  [17] PADCONFIG149_PULLTYPESEL_PROXY rw — Pad Pullup / Pulldown type selection 0 - Pulldown selected 1 - Pullup selected
  [16] PADCONFIG149_PULLUDEN_PROXY rw — Pad Pullup / Pulldown enable. This is an active low signal. 0 - Pullup / Pulldown enabled 1 - Pullup / Pulldown disabled
  [15] PADCONFIG149_FORCE_DS_EN_PROXY rw — Enable pad Deep Sleep controls by overriding WKUP DM gating 0 - Deep Sleep pad controls are gated by the WKUP DM 1 - Activate Deep Sleep pad controls (override WKUP DM gating logic)
  [14] PADCONFIG149_ST_EN_PROXY rw — Receiver Schmitt Trigger enable 0 - Schmitt trigger input disabled 1 - Schmitt trigger input enabled
  [13:11] PADCONFIG149_DEBOUNCE_SEL_PROXY rw — Selects the debouce period for the pad.
  [8] PADCONFIG149_WK_LVL_POL_PROXY rw — Level Sensitive Wakeup Polarity This bit is not relevant unless wk_lvl_en is set to 1'b1. 0 - Low. A low (0) value on the pin causes a wakeup 1 - High. A high (1) value on the pin causes a wakeup
  [7] PADCONFIG149_WK_LVL_EN_PROXY rw — Level Sensitive Wakeup Enable 0 - Disabled. Wakeup is triggered by change of the pin input value 1 - Enabled. Wakeup is triggered when the pin matches the value specified by wk_lvl_pol. The chosen polarity must be maintained. (e.g. until wakeup completion is confirmed)
  [3:0] PADCONFIG149_MUXMODE_PROXY rw — Pad functional signal mux selection Field values (others are reserved): 4'b0000 - Mux Mode 0 4'b0001 - Mux Mode 1 4'b0010 - Mux Mode 2 4'b0011 - Mux Mode 3 4'b0100 - Mux Mode 4 4'b0101 - Mux Mode 5 4'b0110 - Mux Mode 6 4'b0111 - Mux Mode 7 4'b1000 - Mux Mode 8 4'b1001 - Mux Mode 9 4'b1010 - Mux Mode 10 4'b1011 - Mux Mode 11 4'b1100 - Mux Mode 12 4'b1101 - Mux Mode 13 4'b1110 - Mux Mode 14 4'b1111 - Mux Mode 15
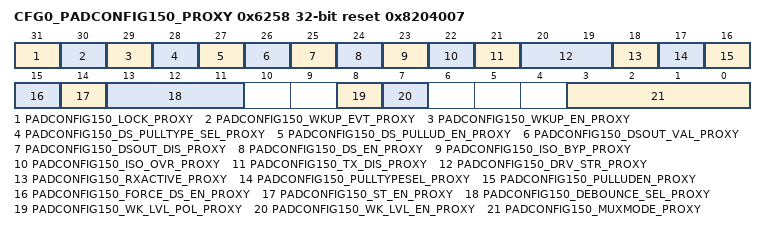
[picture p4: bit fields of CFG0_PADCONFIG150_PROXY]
0x6258 CFG0_PADCONFIG150_PROXY reset 0x8204007
  [31] PADCONFIG150_LOCK_PROXY rw — Lock 0 - Padconfig register is unlocked 1 - Padconfig register is locked from further writes
  [30] PADCONFIG150_WKUP_EVT_PROXY ro — Wakeup event status 0 - No wake event on pin 1 - Wake event occurred on pin
  [29] PADCONFIG150_WKUP_EN_PROXY rw — Wakeup enable 0 - Wakeup operation disabled 1 - Wakeup operation enabled
  [28] PADCONFIG150_DS_PULLTYPE_SEL_PROXY rw — Deep Sleep pull-up/down selection 0 - Offmode pulldown selected 1 - Offmode pullup selected
  [27] PADCONFIG150_DS_PULLUD_EN_PROXY rw — Deep Sleep pull-up/down enable (active low) 0 - Pullup / pulldown is enabled 1 - Pullup / pulldown is disabled
  [26] PADCONFIG150_DSOUT_VAL_PROXY rw — Deep Sleep output value 0 - Output value is 0 1 - Output value is 1
  [25] PADCONFIG150_DSOUT_DIS_PROXY rw — Deep Sleep output disable 0 - Output enabled 1 - Output disabled
  [24] PADCONFIG150_DS_EN_PROXY rw — Deep Sleep override control 0 - IO keeps its previous state when Deep Sleep mode is active 1 - IO state is forced to OFF mode value when Deep Sleep mode is active
  [23] PADCONFIG150_ISO_BYP_PROXY rw — Isolation Bypass 0 - IO isolation is preserved 1 - IO isolation is bypassed
  [22] PADCONFIG150_ISO_OVR_PROXY rw — Isolation Override 0 - IO isolation is preserved 1 - IO isolation is overridden
  [21] PADCONFIG150_TX_DIS_PROXY rw — Driver Disable 0 - Driver is enabled 1 - Driver is disabled
  [20:19] PADCONFIG150_DRV_STR_PROXY rw — Drive Strength Control . Selects the drive strength value for LVCMOS pins. (Does not apply to other pin types)
  [18] PADCONFIG150_RXACTIVE_PROXY rw — Input enable for the Pad 0 - Receiver disabled 1 - Receiver enabled
  [17] PADCONFIG150_PULLTYPESEL_PROXY rw — Pad Pullup / Pulldown type selection 0 - Pulldown selected 1 - Pullup selected
  [16] PADCONFIG150_PULLUDEN_PROXY rw — Pad Pullup / Pulldown enable. This is an active low signal. 0 - Pullup / Pulldown enabled 1 - Pullup / Pulldown disabled
  [15] PADCONFIG150_FORCE_DS_EN_PROXY rw — Enable pad Deep Sleep controls by overriding WKUP DM gating 0 - Deep Sleep pad controls are gated by the WKUP DM 1 - Activate Deep Sleep pad controls (override WKUP DM gating logic)
  [14] PADCONFIG150_ST_EN_PROXY rw — Receiver Schmitt Trigger enable 0 - Schmitt trigger input disabled 1 - Schmitt trigger input enabled
  [13:11] PADCONFIG150_DEBOUNCE_SEL_PROXY rw — Selects the debouce period for the pad.
  [8] PADCONFIG150_WK_LVL_POL_PROXY rw — Level Sensitive Wakeup Polarity This bit is not relevant unless wk_lvl_en is set to 1'b1. 0 - Low. A low (0) value on the pin causes a wakeup 1 - High. A high (1) value on the pin causes a wakeup
  [7] PADCONFIG150_WK_LVL_EN_PROXY rw — Level Sensitive Wakeup Enable 0 - Disabled. Wakeup is triggered by change of the pin input value 1 - Enabled. Wakeup is triggered when the pin matches the value specified by wk_lvl_pol. The chosen polarity must be maintained. (e.g. until wakeup completion is confirmed)
  [3:0] PADCONFIG150_MUXMODE_PROXY rw — Pad functional signal mux selection Field values (others are reserved): 4'b0000 - Mux Mode 0 4'b0001 - Mux Mode 1 4'b0010 - Mux Mode 2 4'b0011 - Mux Mode 3 4'b0100 - Mux Mode 4 4'b0101 - Mux Mode 5 4'b0110 - Mux Mode 6 4'b0111 - Mux Mode 7 4'b1000 - Mux Mode 8 4'b1001 - Mux Mode 9 4'b1010 - Mux Mode 10 4'b1011 - Mux Mode 11 4'b1100 - Mux Mode 12 4'b1101 - Mux Mode 13 4'b1110 - Mux Mode 14 4'b1111 - Mux Mode 15
0x7008 CFG0_LOCK1_KICK0_PROXY rw reset 0x0
  [31:0] LOCK1_KICK0_PROXY — - KICK0 component
0x700C CFG0_LOCK1_KICK1_PROXY rw reset 0x0
  [31:0] LOCK1_KICK1_PROXY — - KICK1 component
{0x7100+4i} CFG0_CLAIMREG_P1_R{i} rw reset 0x0 (i=0..4)
  [31:0] CLAIMREG_P1_R{i} — Claim bits for Partition 1
